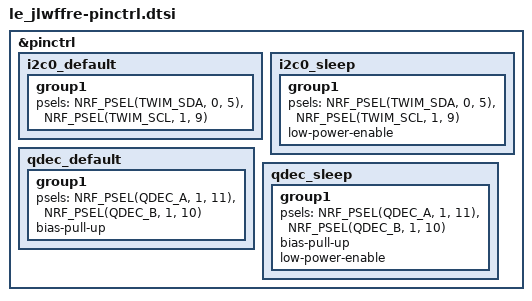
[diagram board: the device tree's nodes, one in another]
/*
 * Copyright (c) 2024 The ZMK Contributors
 *
 * SPDX-License-Identifier: MIT
 */

&pinctrl {
    i2c0_default: i2c0_default {
        group1 {
            psels = <NRF_PSEL(TWIM_SDA, 0, 5)>,
                    <NRF_PSEL(TWIM_SCL, 1, 9)>;
        };
    };

    i2c0_sleep: i2c0_sleep {
        group1 {
            psels = <NRF_PSEL(TWIM_SDA, 0, 5)>,
                    <NRF_PSEL(TWIM_SCL, 1, 9)>;
            low-power-enable;
        };
    };

    qdec_default: qdec_default {
        group1 {
            psels = <NRF_PSEL(QDEC_A, 1, 11)>,
                    <NRF_PSEL(QDEC_B, 1, 10)>;
            bias-pull-up;
        };
    };

    qdec_sleep: qdec_sleep {
        group1 {
            psels = <NRF_PSEL(QDEC_A, 1, 11)>,
                    <NRF_PSEL(QDEC_B, 1, 10)>;
            bias-pull-up;
            low-power-enable;
        };
    };
};
